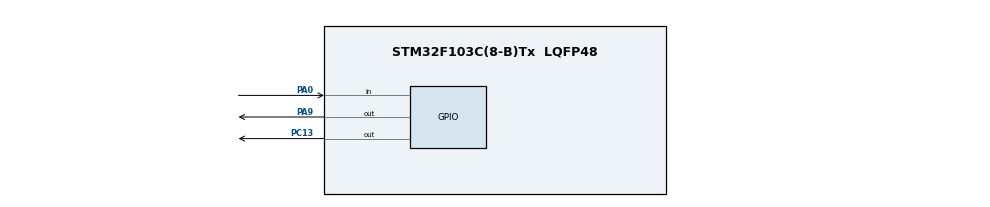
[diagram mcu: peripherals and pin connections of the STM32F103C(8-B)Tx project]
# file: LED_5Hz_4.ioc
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Mcu.Family=STM32F1
Mcu.Name=STM32F103C(8-B)Tx
Mcu.Package=LQFP48
NVIC.PriorityGroup=NVIC_PRIORITYGROUP_4
NVIC.TIM1_UP_IRQn=true\:0\:0\:false\:false\:true\:true\:true\:true
PA0-WKUP.GPIO_PuPd=GPIO_PULLUP
PA0-WKUP.Signal=GPIO_Input
PA13.Mode=Serial_Wire
PA13.Signal=SYS_JTMS-SWDIO
PA14.Mode=Serial_Wire
PA14.Signal=SYS_JTCK-SWCLK
PA9.Signal=GPIO_Output
PC13-TAMPER-RTC.GPIO_ModeDefaultOutputPP=GPIO_MODE_OUTPUT_OD
PC13-TAMPER-RTC.GPIO_PuPd=GPIO_NOPULL
PC13-TAMPER-RTC.PinState=GPIO_PIN_SET
PC13-TAMPER-RTC.Signal=GPIO_Output
ProjectManager.HeapSize=0x200
ProjectManager.StackSize=0x400
ProjectManager.TargetToolchain=MDK-ARM V5.32
RCC.APB1Freq_Value=8000000
RCC.APB2Freq_Value=8000000
TIM1.Period=19
TIM1.Prescaler=7999
VP_TIM1_VS_ClockSourceINT.Mode=Internal
board=custom

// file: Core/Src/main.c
/* USER CODE BEGIN Header */
/**
  ******************************************************************************
  * @file           : main.c
  * @brief          : Main program body
  ******************************************************************************
  * @attention
  *
  * Copyright (c) 2026 STMicroelectronics.
  * All rights reserved.
  *
  * This software is licensed under terms that can be found in the LICENSE file
  * in the root directory of this software component.
  * If no LICENSE file comes with this software, it is provided AS-IS.
  *
  ******************************************************************************
  */
/* USER CODE END Header */
#include "main.h"

TIM_HandleTypeDef htim1;

void SystemClock_Config(void);
static void MX_GPIO_Init(void);
static void MX_TIM1_Init(void);

/* USER CODE BEGIN 0 */
uint8_t mode = 1;//按键模式选择,mode=1为短按模式，mode=2为长按模式
uint8_t key_state_per = 1 ;//上一次按键状态
uint8_t key_state_cur =1;//当前按键状态
uint8_t key_short_flag = 0;//按键短按标志
uint8_t key_long_flag = 0;//按键长按标志
uint8_t time_cnt = 0;//按键时间计数,20ms计一次
uint16_t tick = 0;//系统滴答计数
uint8_t key_cnt = 0;//检测到按键触发次数
/* USER CODE END 0 */

int main(void)
{

  /* MCU Configuration--------------------------------------------------------*/

  /* Reset of all peripherals, Initializes the Flash interface and the Systick. */
  HAL_Init();

  /* Configure the system clock */
  SystemClock_Config();

  /* Initialize all configured peripherals */
  MX_GPIO_Init();
  MX_TIM1_Init();
  /* USER CODE BEGIN 2 */
  HAL_TIM_Base_Start_IT(&htim1);//启动定时器1，并开启中断
  /* USER CODE END 2 */

  /* Infinite loop */
  /* USER CODE BEGIN WHILE */
  while (1)
  {
     if(key_long_flag == 1)//长按标记出现
    {
      if(mode == 1)//短按模式下，长按出现，切换
      {
        mode = 2;
      }
      else if(mode == 2)//长按模式下，长按出现，切换
      {
        mode = 1;
      }
      key_long_flag = 0;
    }
    if(key_short_flag == 1 )//长按标记未出现
    {
      if(mode == 1)
      {
        HAL_GPIO_TogglePin(GPIOC, GPIO_PIN_13);
        HAL_GPIO_TogglePin(GPIOA, GPIO_PIN_9);
      }
      key_short_flag = 0;
    }
    if(mode == 2 && tick >= 5)
  {
    //翻转LED状态
    HAL_GPIO_TogglePin(GPIOC, GPIO_PIN_13);
    HAL_GPIO_TogglePin(GPIOA, GPIO_PIN_9);
    tick = 0;
  }

    /* USER CODE END WHILE */

  }
}

void SystemClock_Config(void)
{
  RCC_OscInitTypeDef RCC_OscInitStruct = {0};
  RCC_ClkInitTypeDef RCC_ClkInitStruct = {0};

  /** Initializes the RCC Oscillators according to the specified parameters
  * in the RCC_OscInitTypeDef structure.
  */
  RCC_OscInitStruct.OscillatorType = RCC_OSCILLATORTYPE_HSI;
  RCC_OscInitStruct.HSIState = RCC_HSI_ON;
  RCC_OscInitStruct.HSICalibrationValue = RCC_HSICALIBRATION_DEFAULT;
  RCC_OscInitStruct.PLL.PLLState = RCC_PLL_NONE;
  if (HAL_RCC_OscConfig(&RCC_OscInitStruct) != HAL_OK)
  {
    Error_Handler();
  }

  /** Initializes the CPU, AHB and APB buses clocks
  */
  RCC_ClkInitStruct.ClockType = RCC_CLOCKTYPE_HCLK|RCC_CLOCKTYPE_SYSCLK
                              |RCC_CLOCKTYPE_PCLK1|RCC_CLOCKTYPE_PCLK2;
  RCC_ClkInitStruct.SYSCLKSource = RCC_SYSCLKSOURCE_HSI;
  RCC_ClkInitStruct.AHBCLKDivider = RCC_SYSCLK_DIV1;
  RCC_ClkInitStruct.APB1CLKDivider = RCC_HCLK_DIV1;
  RCC_ClkInitStruct.APB2CLKDivider = RCC_HCLK_DIV1;

  if (HAL_RCC_ClockConfig(&RCC_ClkInitStruct, FLASH_LATENCY_0) != HAL_OK)
  {
    Error_Handler();
  }
}

static void MX_TIM1_Init(void)
{

  TIM_ClockConfigTypeDef sClockSourceConfig = {0};
  TIM_MasterConfigTypeDef sMasterConfig = {0};

  htim1.Instance = TIM1;
  htim1.Init.Prescaler = 7999;
  htim1.Init.CounterMode = TIM_COUNTERMODE_UP;
  htim1.Init.Period = 19;
  htim1.Init.ClockDivision = TIM_CLOCKDIVISION_DIV1;
  htim1.Init.RepetitionCounter = 0;
  htim1.Init.AutoReloadPreload = TIM_AUTORELOAD_PRELOAD_DISABLE;
  if (HAL_TIM_Base_Init(&htim1) != HAL_OK)
  {
    Error_Handler();
  }
  sClockSourceConfig.ClockSource = TIM_CLOCKSOURCE_INTERNAL;
  if (HAL_TIM_ConfigClockSource(&htim1, &sClockSourceConfig) != HAL_OK)
  {
    Error_Handler();
  }
  sMasterConfig.MasterOutputTrigger = TIM_TRGO_RESET;
  sMasterConfig.MasterSlaveMode = TIM_MASTERSLAVEMODE_DISABLE;
  if (HAL_TIMEx_MasterConfigSynchronization(&htim1, &sMasterConfig) != HAL_OK)
  {
    Error_Handler();
  }

}

static void MX_GPIO_Init(void)
{
  GPIO_InitTypeDef GPIO_InitStruct = {0};

  /* GPIO Ports Clock Enable */
  __HAL_RCC_GPIOC_CLK_ENABLE();
  __HAL_RCC_GPIOA_CLK_ENABLE();

  /*Configure GPIO pin Output Level */
  HAL_GPIO_WritePin(GPIOC, GPIO_PIN_13, GPIO_PIN_SET);

  /*Configure GPIO pin Output Level */
  HAL_GPIO_WritePin(GPIOA, GPIO_PIN_9, GPIO_PIN_RESET);

  /*Configure GPIO pin : PC13 */
  GPIO_InitStruct.Pin = GPIO_PIN_13;
  GPIO_InitStruct.Mode = GPIO_MODE_OUTPUT_OD;
  GPIO_InitStruct.Pull = GPIO_NOPULL;
  GPIO_InitStruct.Speed = GPIO_SPEED_FREQ_LOW;
  HAL_GPIO_Init(GPIOC, &GPIO_InitStruct);

  /*Configure GPIO pin : PA0 */
  GPIO_InitStruct.Pin = GPIO_PIN_0;
  GPIO_InitStruct.Mode = GPIO_MODE_INPUT;
  GPIO_InitStruct.Pull = GPIO_PULLUP;
  HAL_GPIO_Init(GPIOA, &GPIO_InitStruct);

  /*Configure GPIO pin : PA9 */
  GPIO_InitStruct.Pin = GPIO_PIN_9;
  GPIO_InitStruct.Mode = GPIO_MODE_OUTPUT_PP;
  GPIO_InitStruct.Pull = GPIO_NOPULL;
  GPIO_InitStruct.Speed = GPIO_SPEED_FREQ_LOW;
  HAL_GPIO_Init(GPIOA, &GPIO_InitStruct);

}

/* USER CODE BEGIN 4 */

void HAL_TIM_PeriodElapsedCallback(TIM_HandleTypeDef *htim)
{
  if(htim == &htim1)//判断是否为定时器1
  {
    key_state_cur = HAL_GPIO_ReadPin(GPIOA, GPIO_PIN_0);
    if(key_state_cur == 0 && key_state_per != key_state_cur)//按键刚刚按下
    {
        time_cnt = 0;
    }
    else if(key_state_cur == 0 && key_state_per == key_state_cur)//按键保持按下
    {
      time_cnt++;
    }
    else if(key_state_cur == 1 && key_state_per != key_state_cur)//按键刚刚松开,判断按键按下时间长短
    {
        if(time_cnt >= 50 )//识别触发长按
      {
        key_long_flag = 1;
      }
        else if(time_cnt >= 2) //识别触发短按,过滤抖动
      {
        key_short_flag = 1;
      }
      time_cnt = 0;
    }
      tick++;
      key_state_per = key_state_cur;
  }
  }

/* USER CODE END 4 */

void Error_Handler(void)
{
  __disable_irq();
  while (1)
  {
  }
}
